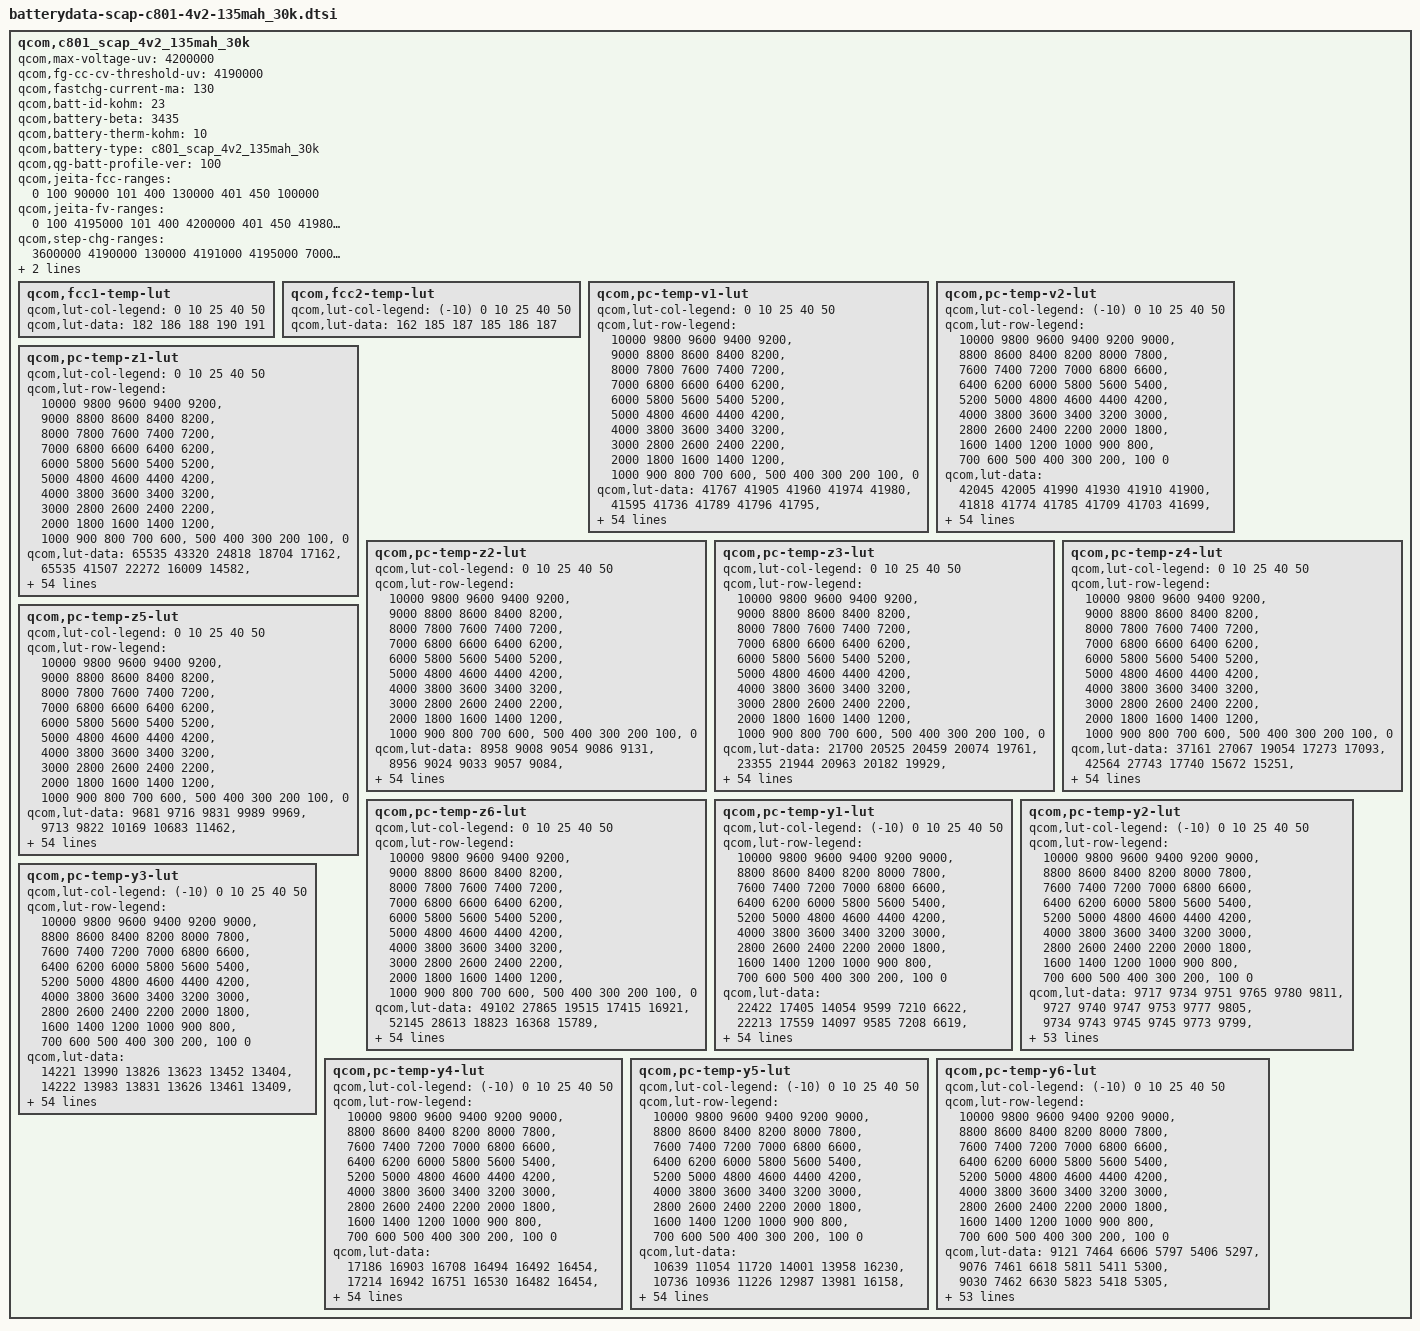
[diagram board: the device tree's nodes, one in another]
/* Copyright (c) 2015-2016, The Linux Foundation. All rights reserved.
 *
 * This program is free software; you can redistribute it and/or modify
 * it under the terms of the GNU General Public License version 2 and
 * only version 2 as published by the Free Software Foundation.
 *
 * This program is distributed in the hope that it will be useful,
 * but WITHOUT ANY WARRANTY; without even the implied warranty of
 * MERCHANTABILITY or FITNESS FOR A PARTICULAR PURPOSE.  See the
 * GNU General Public License for more details.
 */

qcom,c801_scap_4v2_135mah_30k {
	/* #batterydata-scap-c801-4v2-135mah_30k_FG_averaged_MasterSlave_Apr8th2020*/
	qcom,max-voltage-uv = <4200000>;
	qcom,fg-cc-cv-threshold-uv = <4190000>;
	qcom,fastchg-current-ma = <130>;
	qcom,batt-id-kohm = <23>;
	qcom,battery-beta = <3435>;
	qcom,battery-therm-kohm = <10>;
	qcom,battery-type = "c801_scap_4v2_135mah_30k";
	qcom,qg-batt-profile-ver = <100>;

	qcom,jeita-fcc-ranges = <0   100  90000
				101  400  130000
				401  450  100000>;
	qcom,jeita-fv-ranges = <0   100  4195000
				101 400  4200000
				401 450  4198000>;
	qcom,step-chg-ranges = <3600000  4190000  130000
				4191000  4195000  70000
				4196000  4200000  50000>;

	/* COOL = 0 DegC, WARM = 45 DegC */
	qcom,jeita-soft-thresholds = <0x3730 0x0FB0>;
	/* COLD = -10 DegC, HOT = 50 DegC */
	qcom,jeita-hard-thresholds = <0x448E 0x0D8F>;

	qcom,fcc1-temp-lut {
		qcom,lut-col-legend = <0 10 25 40 50>;
		qcom,lut-data = <182 186 188 190 191>;
	};

	qcom,fcc2-temp-lut {
		qcom,lut-col-legend = <(-10) 0 10 25 40 50>;
		qcom,lut-data = <162 185 187 185 186 187>;
	};

	qcom,pc-temp-v1-lut {
		qcom,lut-col-legend = <0 10 25 40 50>;
		qcom,lut-row-legend = <10000 9800 9600 9400 9200>,
			<9000 8800 8600 8400 8200>,
			<8000 7800 7600 7400 7200>,
			<7000 6800 6600 6400 6200>,
			<6000 5800 5600 5400 5200>,
			<5000 4800 4600 4400 4200>,
			<4000 3800 3600 3400 3200>,
			<3000 2800 2600 2400 2200>,
			<2000 1800 1600 1400 1200>,
			<1000 900 800 700 600>,
			<500 400 300 200 100>,
			<0>;
		qcom,lut-data = <41767 41905 41960 41974 41980>,
			<41595 41736 41789 41796 41795>,
			<41416 41555 41609 41610 41608>,
			<41245 41375 41429 41424 41421>,
			<41107 41204 41249 41241 41238>,
			<41024 41063 41073 41061 41057>,
			<40894 40972 40929 40888 40881>,
			<40518 40797 40837 40756 40717>,
			<40198 40429 40625 40612 40564>,
			<39987 40142 40303 40371 40379>,
			<39845 39965 40072 40159 40201>,
			<39743 39843 39933 40019 40053>,
			<39660 39749 39837 39902 39917>,
			<39581 39664 39742 39782 39782>,
			<39426 39567 39630 39654 39650>,
			<39133 39419 39508 39523 39518>,
			<39054 39297 39399 39395 39379>,
			<38951 39205 39281 39233 39227>,
			<38840 39101 39161 39070 39070>,
			<38727 39006 39032 38933 38919>,
			<38622 38917 38857 38798 38780>,
			<38530 38828 38698 38668 38655>,
			<38439 38741 38590 38563 38549>,
			<38351 38660 38502 38472 38456>,
			<38265 38582 38425 38390 38370>,
			<38182 38506 38352 38313 38291>,
			<38102 38430 38283 38240 38218>,
			<38027 38351 38219 38174 38153>,
			<37954 38282 38161 38114 38094>,
			<37890 38223 38107 38059 38038>,
			<37837 38172 38062 38010 37988>,
			<37783 38126 38024 37967 37942>,
			<37727 38082 37987 37929 37899>,
			<37670 38034 37953 37893 37856>,
			<37616 37987 37922 37851 37801>,
			<37571 37950 37885 37803 37741>,
			<37523 37915 37843 37747 37681>,
			<37460 37873 37776 37676 37614>,
			<37414 37819 37686 37589 37534>,
			<37407 37749 37599 37503 37445>,
			<37431 37659 37500 37403 37341>,
			<37466 37543 37380 37274 37214>,
			<37475 37427 37261 37147 37086>,
			<37442 37315 37152 37031 36967>,
			<37320 37212 37081 36976 36910>,
			<37210 37140 37037 36942 36877>,
			<37174 37110 37018 36927 36864>,
			<37154 37080 36990 36896 36831>,
			<37074 37000 36876 36773 36701>,
			<36850 36736 36585 36477 36402>,
			<36452 36360 36212 36105 36030>,
			<35986 35897 35753 35645 35572>,
			<35394 35321 35171 35064 34993>,
			<34600 34545 34390 34284 34217>,
			<33389 33377 33202 33106 33048>,
			<30000 30000 30000 30000 30000>;
	};

	qcom,pc-temp-v2-lut {
		qcom,lut-col-legend = <(-10) 0 10 25 40 50>;
		qcom,lut-row-legend = <10000 9800 9600 9400 9200 9000>,
			<8800 8600 8400 8200 8000 7800>,
			<7600 7400 7200 7000 6800 6600>,
			<6400 6200 6000 5800 5600 5400>,
			<5200 5000 4800 4600 4400 4200>,
			<4000 3800 3600 3400 3200 3000>,
			<2800 2600 2400 2200 2000 1800>,
			<1600 1400 1200 1000 900 800>,
			<700 600 500 400 300 200>,
			<100 0>;
		qcom,lut-data = <42045 42005 41990 41930 41910 41900>,
			<41818 41774 41785 41709 41703 41699>,
			<41615 41563 41589 41506 41508 41506>,
			<41440 41375 41400 41320 41324 41321>,
			<41277 41190 41213 41138 41144 41141>,
			<41100 41010 41031 40962 40968 40965>,
			<40942 40898 40906 40842 40816 40796>,
			<40837 40789 40778 40727 40669 40633>,
			<40724 40517 40556 40494 40495 40470>,
			<40514 40193 40277 40237 40309 40305>,
			<40234 39884 39945 40007 40109 40137>,
			<39906 39679 39733 39866 39961 39990>,
			<39616 39543 39589 39777 39848 39858>,
			<39430 39439 39483 39669 39721 39722>,
			<39291 39345 39383 39540 39586 39586>,
			<39182 39242 39266 39360 39446 39444>,
			<39092 39128 39142 39180 39281 39286>,
			<39011 38996 39011 39025 39080 39109>,
			<38931 38869 38887 38888 38914 38941>,
			<38841 38746 38769 38766 38776 38787>,
			<38745 38629 38657 38655 38658 38661>,
			<38647 38518 38551 38553 38554 38552>,
			<38550 38412 38449 38457 38459 38454>,
			<38455 38313 38354 38369 38371 38366>,
			<38363 38223 38265 38288 38289 38285>,
			<38276 38137 38181 38210 38213 38210>,
			<38190 38053 38099 38135 38143 38140>,
			<38105 37975 38021 38067 38076 38073>,
			<38024 37900 37949 38002 38012 38012>,
			<37947 37831 37882 37941 37951 37952>,
			<37868 37765 37814 37881 37894 37892>,
			<37791 37712 37768 37831 37829 37829>,
			<37714 37673 37716 37775 37763 37760>,
			<37640 37630 37659 37713 37688 37667>,
			<37570 37585 37602 37644 37615 37575>,
			<37490 37537 37557 37580 37536 37493>,
			<37423 37484 37501 37521 37461 37414>,
			<37339 37427 37444 37466 37390 37335>,
			<37268 37356 37385 37404 37329 37270>,
			<37201 37291 37316 37327 37256 37199>,
			<37124 37233 37229 37239 37155 37097>,
			<37040 37177 37138 37151 37061 37000>,
			<36945 37117 37077 37028 36940 36882>,
			<36827 37050 37031 36939 36847 36788>,
			<36673 36970 36986 36912 36830 36773>,
			<36460 36842 36920 36883 36809 36749>,
			<36329 36748 36867 36853 36779 36720>,
			<36168 36608 36760 36788 36684 36620>,
			<35977 36421 36581 36616 36427 36342>,
			<35746 36173 36323 36308 36063 35989>,
			<35459 35861 35970 35911 35645 35575>,
			<35081 35444 35515 35407 35150 35073>,
			<34539 34878 34908 34774 34519 34432>,
			<33776 34050 34081 33933 33654 33554>,
			<32656 32779 32857 32559 32262 32141>,
			<31049 30092 30438 30331 30552 30544>;
	};

	qcom,pc-temp-z1-lut {
		qcom,lut-col-legend = <0 10 25 40 50>;
		qcom,lut-row-legend = <10000 9800 9600 9400 9200>,
			<9000 8800 8600 8400 8200>,
			<8000 7800 7600 7400 7200>,
			<7000 6800 6600 6400 6200>,
			<6000 5800 5600 5400 5200>,
			<5000 4800 4600 4400 4200>,
			<4000 3800 3600 3400 3200>,
			<3000 2800 2600 2400 2200>,
			<2000 1800 1600 1400 1200>,
			<1000 900 800 700 600>,
			<500 400 300 200 100>,
			<0>;
		qcom,lut-data = <65535 43320 24818 18704 17162>,
			<65535 41507 22272 16009 14582>,
			<65535 41113 22126 15951 14529>,
			<65535 41531 22114 15964 14538>,
			<65535 41579 22209 15978 14553>,
			<65535 41989 22253 15982 14554>,
			<59786 41353 22290 15990 14564>,
			<51736 41056 22335 16037 14571>,
			<48514 39747 22277 16031 14578>,
			<46794 38711 22269 16015 14567>,
			<45720 38634 22219 16003 14605>,
			<45345 38560 22208 16003 14584>,
			<44036 38786 22234 16033 14583>,
			<43542 38602 22333 16038 14595>,
			<39424 38845 22391 16055 14598>,
			<35287 36282 22371 16069 14615>,
			<35502 34942 22237 16071 14622>,
			<35636 35303 22338 16089 14623>,
			<35763 35694 22433 16117 14631>,
			<36016 36067 22505 16133 14643>,
			<36275 36389 22561 16156 14655>,
			<36451 36906 22613 16181 14664>,
			<36579 37530 22666 16190 14678>,
			<36848 37796 22689 16199 14688>,
			<37049 38032 22722 16220 14692>,
			<37186 38490 22755 16234 14697>,
			<37325 39020 22800 16243 14709>,
			<37443 39535 22858 16256 14717>,
			<37542 39745 22933 16269 14723>,
			<37673 39829 22999 16282 14726>,
			<37896 39865 23058 16297 14731>,
			<38065 39975 23108 16317 14743>,
			<38217 40298 23110 16343 14758>,
			<38555 40574 23115 16373 14777>,
			<38990 40768 23219 16401 14803>,
			<39281 40971 23322 16432 14822>,
			<39600 41177 23413 16465 14828>,
			<40003 41343 23504 16486 14836>,
			<40544 41483 23607 16501 14848>,
			<41294 41665 23702 16526 14864>,
			<42191 41704 23739 16547 14880>,
			<43414 41617 23742 16558 14890>,
			<45722 41518 23755 16573 14898>,
			<48703 41345 23790 16595 14905>,
			<51740 41274 23862 16620 14918>,
			<53244 41626 23876 16634 14930>,
			<53816 41866 23865 16637 14933>,
			<53957 41193 23878 16636 14932>,
			<54066 41423 23937 16641 14937>,
			<54988 41400 24014 16685 14966>,
			<54106 41827 24190 16738 14997>,
			<54252 42128 24266 16812 15042>,
			<55592 42034 24522 16894 15085>,
			<54264 42643 24807 17026 15192>,
			<54264 42643 24807 17026 15192>,
			<54264 42643 24807 17026 15192>;
	};

	qcom,pc-temp-z2-lut {
		qcom,lut-col-legend = <0 10 25 40 50>;
		qcom,lut-row-legend = <10000 9800 9600 9400 9200>,
			<9000 8800 8600 8400 8200>,
			<8000 7800 7600 7400 7200>,
			<7000 6800 6600 6400 6200>,
			<6000 5800 5600 5400 5200>,
			<5000 4800 4600 4400 4200>,
			<4000 3800 3600 3400 3200>,
			<3000 2800 2600 2400 2200>,
			<2000 1800 1600 1400 1200>,
			<1000 900 800 700 600>,
			<500 400 300 200 100>,
			<0>;
		qcom,lut-data = <8958 9008 9054 9086 9131>,
			<8956 9024 9033 9057 9084>,
			<8979 9031 9034 9059 9098>,
			<8981 9032 9036 9067 9097>,
			<8962 9037 9042 9067 9100>,
			<8954 9037 9046 9067 9097>,
			<8959 9041 9046 9065 9098>,
			<8987 9039 9048 9067 9096>,
			<8971 9047 9045 9065 9099>,
			<8973 9060 9043 9062 9094>,
			<8975 9066 9047 9064 9096>,
			<8978 9066 9049 9067 9097>,
			<8978 9063 9049 9072 9098>,
			<8979 9055 9048 9070 9099>,
			<8983 9069 9050 9071 9099>,
			<8988 9047 9049 9069 9095>,
			<8989 9024 9035 9060 9092>,
			<8988 9024 9034 9058 9088>,
			<8987 9025 9034 9058 9087>,
			<8987 9024 9034 9058 9083>,
			<8986 9020 9032 9057 9080>,
			<8984 9019 9031 9056 9079>,
			<8983 9019 9032 9053 9078>,
			<8982 9019 9032 9051 9076>,
			<8981 9018 9032 9051 9075>,
			<8978 9017 9031 9051 9075>,
			<8977 9019 9030 9049 9077>,
			<8976 9041 9029 9049 9080>,
			<8975 9045 9028 9049 9085>,
			<8975 9042 9027 9052 9087>,
			<8975 9040 9026 9052 9089>,
			<8976 9038 9026 9052 9092>,
			<8976 9038 9024 9053 9091>,
			<8976 9043 9023 9054 9089>,
			<8976 9057 9024 9056 9096>,
			<8978 9056 9024 9057 9102>,
			<8979 9053 9023 9057 9098>,
			<8982 9050 9024 9056 9099>,
			<8982 9046 9025 9055 9103>,
			<8983 9039 9024 9057 9104>,
			<8987 9032 9023 9058 9103>,
			<8995 9023 9023 9056 9100>,
			<9000 9016 9021 9054 9099>,
			<9001 9011 9016 9052 9099>,
			<9002 9009 9013 9051 9098>,
			<9006 9008 9013 9051 9097>,
			<8998 9008 9015 9051 9098>,
			<8957 9014 9018 9055 9107>,
			<8954 9013 9020 9063 9108>,
			<8954 9006 9018 9062 9103>,
			<8969 9003 9013 9058 9095>,
			<8973 8995 9009 9053 9093>,
			<8973 8986 9005 9047 9082>,
			<8970 8981 9000 9040 9077>,
			<8970 8981 9000 9040 9077>,
			<8970 8981 9000 9040 9077>;
	};

	qcom,pc-temp-z3-lut {
		qcom,lut-col-legend = <0 10 25 40 50>;
		qcom,lut-row-legend = <10000 9800 9600 9400 9200>,
			<9000 8800 8600 8400 8200>,
			<8000 7800 7600 7400 7200>,
			<7000 6800 6600 6400 6200>,
			<6000 5800 5600 5400 5200>,
			<5000 4800 4600 4400 4200>,
			<4000 3800 3600 3400 3200>,
			<3000 2800 2600 2400 2200>,
			<2000 1800 1600 1400 1200>,
			<1000 900 800 700 600>,
			<500 400 300 200 100>,
			<0>;
		qcom,lut-data = <21700 20525 20459 20074 19761>,
			<23355 21944 20963 20182 19929>,
			<23936 22381 20978 20074 19829>,
			<24263 22491 20816 20006 19821>,
			<24259 22375 20620 19995 19806>,
			<25067 22254 20560 20007 19813>,
			<31310 22053 20527 20006 19813>,
			<28655 21908 20473 19969 19811>,
			<22527 21796 20537 20009 19807>,
			<21379 21497 20602 19996 19836>,
			<20995 21208 20498 19982 19817>,
			<20770 21127 20400 19928 19790>,
			<20664 21082 20411 19905 19783>,
			<20565 21002 20412 19886 19753>,
			<20367 21151 20362 19889 19777>,
			<20627 21236 20362 19920 19775>,
			<20705 21209 20746 20027 19815>,
			<20723 21202 20748 20191 19900>,
			<20715 21160 20866 20233 19943>,
			<20687 21106 21116 20226 20042>,
			<20652 21034 21203 20264 20087>,
			<20589 20979 21231 20356 20093>,
			<20495 20911 21202 20329 20060>,
			<20366 20809 21153 20268 20018>,
			<20222 20744 21088 20185 20013>,
			<20088 20713 21040 20170 20004>,
			<20000 20766 21000 20175 19965>,
			<19937 21704 20961 20175 19903>,
			<19888 21937 20949 20175 19842>,
			<19838 21929 20962 20153 19828>,
			<19786 21721 20944 20132 19815>,
			<19767 21476 20897 20119 19792>,
			<19763 21583 20925 20101 19802>,
			<19765 22082 20964 20080 19834>,
			<19759 23359 20990 20068 19820>,
			<19709 23391 21001 20056 19808>,
			<19663 23254 20995 20044 19811>,
			<19634 23264 21043 20051 19803>,
			<19634 23375 21109 20071 19785>,
			<19663 23531 21075 20044 19787>,
			<19594 23741 21066 20022 19793>,
			<19464 24030 21173 20056 19803>,
			<19424 23944 21172 20087 19819>,
			<19457 23593 21090 20108 19838>,
			<22510 23199 21029 20023 19787>,
			<24568 22345 20831 19928 19723>,
			<24046 21673 20624 19906 19707>,
			<20300 21027 20456 19856 19686>,
			<20136 20852 20484 19837 19717>,
			<20172 21418 20534 19866 19765>,
			<22384 21708 20558 19892 19782>,
			<22629 22012 20576 19926 19792>,
			<23184 22086 20639 19947 19822>,
			<23534 22193 20637 20003 19835>,
			<23534 22193 20637 20003 19835>,
			<23534 22193 20637 20003 19835>;
	};

	qcom,pc-temp-z4-lut {
		qcom,lut-col-legend = <0 10 25 40 50>;
		qcom,lut-row-legend = <10000 9800 9600 9400 9200>,
			<9000 8800 8600 8400 8200>,
			<8000 7800 7600 7400 7200>,
			<7000 6800 6600 6400 6200>,
			<6000 5800 5600 5400 5200>,
			<5000 4800 4600 4400 4200>,
			<4000 3800 3600 3400 3200>,
			<3000 2800 2600 2400 2200>,
			<2000 1800 1600 1400 1200>,
			<1000 900 800 700 600>,
			<500 400 300 200 100>,
			<0>;
		qcom,lut-data = <37161 27067 19054 17273 17093>,
			<42564 27743 17740 15672 15251>,
			<40139 23761 16538 15234 14985>,
			<36522 21453 16039 15146 14977>,
			<34327 20043 15740 15151 14981>,
			<32622 19270 15640 15123 14970>,
			<29851 18723 15678 15134 14965>,
			<24200 18032 15627 15172 14977>,
			<25022 17293 15512 15090 14949>,
			<24197 16794 15484 15087 14916>,
			<23452 16642 15582 15119 14933>,
			<23126 16703 15633 15150 14955>,
			<22861 16716 15574 15142 14949>,
			<22382 16732 15551 15152 14965>,
			<23514 16577 15585 15140 14938>,
			<26911 19062 15576 15120 14953>,
			<26807 21107 16025 15243 15061>,
			<26889 21007 15968 15555 15327>,
			<27081 20984 15837 15839 15497>,
			<27380 20962 15697 16026 15613>,
			<27669 20933 16273 16114 15683>,
			<27916 20939 16819 16165 15723>,
			<28224 20961 16915 16123 15685>,
			<28609 21022 16911 16046 15583>,
			<29044 21075 16824 15950 15476>,
			<29499 21114 16747 15827 15397>,
			<29923 21064 16670 15689 15351>,
			<30327 20053 16588 15581 15337>,
			<30745 19830 16495 15496 15326>,
			<31109 19880 16386 15438 15291>,
			<31400 20128 16291 15403 15268>,
			<31713 20382 16202 15380 15261>,
			<32049 20246 16068 15379 15262>,
			<32417 19659 15944 15385 15272>,
			<32799 18209 15856 15440 15363>,
			<33137 18146 15821 15499 15428>,
			<33478 18207 15816 15531 15382>,
			<33913 18095 15888 15578 15370>,
			<34166 17919 16023 15626 15378>,
			<33805 17727 16078 15574 15329>,
			<33192 17603 16130 15537 15278>,
			<32332 17527 16196 15702 15351>,
			<31385 17607 16232 15746 15404>,
			<30252 17802 16250 15723 15429>,
			<25686 17839 15943 15511 15298>,
			<20958 17969 15675 15163 15027>,
			<19856 18079 15606 15026 14913>,
			<20795 17316 15396 14978 14879>,
			<20507 16985 15319 15054 14878>,
			<20324 16471 15468 15102 14871>,
			<18420 16529 15540 15101 14877>,
			<18443 16499 15640 15110 14896>,
			<18426 16780 15713 15143 14915>,
			<18543 17026 15884 15157 14952>,
			<18543 17026 15884 15157 14952>,
			<18543 17026 15884 15157 14952>;
	};

	qcom,pc-temp-z5-lut {
		qcom,lut-col-legend = <0 10 25 40 50>;
		qcom,lut-row-legend = <10000 9800 9600 9400 9200>,
			<9000 8800 8600 8400 8200>,
			<8000 7800 7600 7400 7200>,
			<7000 6800 6600 6400 6200>,
			<6000 5800 5600 5400 5200>,
			<5000 4800 4600 4400 4200>,
			<4000 3800 3600 3400 3200>,
			<3000 2800 2600 2400 2200>,
			<2000 1800 1600 1400 1200>,
			<1000 900 800 700 600>,
			<500 400 300 200 100>,
			<0>;
		qcom,lut-data = <9681 9716 9831 9989 9969>,
			<9713 9822 10169 10683 11462>,
			<9751 9928 10373 10861 11885>,
			<9779 10039 10434 11000 11827>,
			<9776 10114 10499 10938 11559>,
			<9782 10147 10567 10967 11727>,
			<9810 10184 10454 10893 11664>,
			<9959 10225 10444 10742 11526>,
			<9761 10474 10534 10944 11570>,
			<9753 10610 10606 10823 11948>,
			<9753 10543 10399 10747 11706>,
			<9752 10462 10313 10611 11397>,
			<9757 10394 10372 10560 11230>,
			<9771 10326 10370 10488 11021>,
			<10147 10434 10281 10508 11270>,
			<10881 10365 10305 10646 11297>,
			<10886 10187 10140 10753 11273>,
			<10871 10160 10179 11650 11182>,
			<10836 10128 10441 11912 11004>,
			<10805 10086 11102 11101 11123>,
			<10772 10033 11775 10934 11149>,
			<10726 9994 12057 10939 10890>,
			<10674 9956 11644 10758 10667>,
			<10622 9914 11225 10499 10559>,
			<10568 9881 10896 10343 10645>,
			<10515 9859 10690 10333 10720>,
			<10467 9862 10553 10409 10749>,
			<10425 10076 10448 10512 10667>,
			<10393 10124 10414 10637 10559>,
			<10364 10111 10427 10743 10636>,
			<10331 10027 10408 10857 10732>,
			<10296 9930 10360 10982 10783>,
			<10264 9944 10411 11062 10994>,
			<10247 10026 10510 11105 11331>,
			<10233 10249 10629 11088 11182>,
			<10206 10239 10710 11040 11040>,
			<10176 10176 10776 10911 11022>,
			<10149 10171 11007 10938 10999>,
			<10113 10203 11280 11050 10962>,
			<10053 10251 11047 10952 11054>,
			<9981 10338 10938 10858 11143>,
			<9898 10497 11204 10853 10961>,
			<9806 10441 11140 10847 10865>,
			<9746 10248 10785 10836 10840>,
			<9966 10109 10672 10724 10857>,
			<10082 9921 10365 10791 11259>,
			<10022 9849 10137 11058 11874>,
			<9743 9865 10202 11233 11959>,
			<9730 9877 10743 10899 11934>,
			<9732 10160 10616 10722 12283>,
			<10039 10223 10507 10729 12423>,
			<10031 10318 10371 10761 12330>,
			<10080 10174 10305 10656 12494>,
			<10070 10094 10135 10673 12158>,
			<10070 10094 10135 10673 12158>,
			<10070 10094 10135 10673 12158>;
	};

	qcom,pc-temp-z6-lut {
		qcom,lut-col-legend = <0 10 25 40 50>;
		qcom,lut-row-legend = <10000 9800 9600 9400 9200>,
			<9000 8800 8600 8400 8200>,
			<8000 7800 7600 7400 7200>,
			<7000 6800 6600 6400 6200>,
			<6000 5800 5600 5400 5200>,
			<5000 4800 4600 4400 4200>,
			<4000 3800 3600 3400 3200>,
			<3000 2800 2600 2400 2200>,
			<2000 1800 1600 1400 1200>,
			<1000 900 800 700 600>,
			<500 400 300 200 100>,
			<0>;
		qcom,lut-data = <49102 27865 19515 17415 16921>,
			<52145 28613 18823 16368 15789>,
			<51812 27203 18292 16109 15603>,
			<50623 26317 17997 16028 15597>,
			<49758 25717 17767 16028 15593>,
			<49097 25382 17699 16025 15592>,
			<45015 25085 17704 16031 15592>,
			<36034 24684 17664 16035 15597>,
			<31011 24054 17640 16019 15586>,
			<29262 23476 17658 16011 15584>,
			<28257 23148 17637 16013 15584>,
			<27779 23109 17602 15999 15579>,
			<27308 23140 17591 15988 15572>,
			<26665 23119 17593 15983 15568>,
			<25765 23070 17593 15983 15568>,
			<25856 23293 17585 15991 15576>,
			<25909 23715 17980 16107 15647>,
			<26016 23743 17973 16336 15811>,
			<26152 23830 17992 16482 15912>,
			<26323 23892 18076 16556 16018>,
			<26483 23963 18388 16633 16075>,
			<26613 24055 18628 16700 16099>,
			<26758 24163 18665 16673 16070>,
			<26921 24269 18655 16612 16003>,
			<27097 24388 18587 16535 15957>,
			<27289 24526 18537 16471 15916>,
			<27496 24667 18495 16420 15878>,
			<27707 24841 18454 16376 15838>,
			<27925 24976 18418 16338 15802>,
			<28130 25074 18387 16304 15778>,
			<28310 25132 18347 16279 15760>,
			<28507 25181 18294 16261 15745>,
			<28724 25242 18253 16251 15748>,
			<28969 25329 18229 16248 15771>,
			<29226 25440 18220 16269 15810>,
			<29459 25494 18222 16294 15832>,
			<29710 25514 18237 16308 15817>,
			<30059 25500 18308 16336 15809>,
			<30306 25497 18416 16370 15803>,
			<30389 25522 18437 16340 15786>,
			<30364 25567 18470 16319 15772>,
			<30413 25669 18569 16412 15812>,
			<30779 25653 18583 16452 15849>,
			<31493 25557 18562 16460 15874>,
			<32868 25389 18427 16336 15793>,
			<33799 25055 18205 16142 15644>,
			<33867 24749 18080 16072 15587>,
			<32974 24103 17884 16010 15550>,
			<32833 23874 17866 16027 15564>,
			<32817 23962 17984 16078 15593>,
			<33120 24182 18068 16108 15614>,
			<33213 24386 18168 16151 15641>,
			<33463 24600 18292 16202 15677>,
			<33681 24887 18466 16278 15729>,
			<33681 24887 18466 16278 15729>,
			<33681 24887 18466 16278 15729>;
	};

	qcom,pc-temp-y1-lut {
		qcom,lut-col-legend = <(-10) 0 10 25 40 50>;
		qcom,lut-row-legend = <10000 9800 9600 9400 9200 9000>,
			<8800 8600 8400 8200 8000 7800>,
			<7600 7400 7200 7000 6800 6600>,
			<6400 6200 6000 5800 5600 5400>,
			<5200 5000 4800 4600 4400 4200>,
			<4000 3800 3600 3400 3200 3000>,
			<2800 2600 2400 2200 2000 1800>,
			<1600 1400 1200 1000 900 800>,
			<700 600 500 400 300 200>,
			<100 0>;
		qcom,lut-data = <22422 17405 14054 9599 7210 6622>,
			<22213 17559 14097 9585 7208 6619>,
			<21916 17611 14105 9563 7208 6618>,
			<21646 17602 14089 9545 7208 6618>,
			<21520 17543 14049 9542 7212 6620>,
			<21537 17421 13976 9544 7220 6625>,
			<21584 17446 13959 9529 7222 6629>,
			<21676 17517 13957 9506 7222 6632>,
			<21779 17561 13960 9517 7220 6632>,
			<21789 17606 13989 9554 7225 6634>,
			<21812 17680 14152 9700 7297 6652>,
			<22047 17754 14264 9785 7334 6663>,
			<22140 17845 14335 9823 7350 6669>,
			<22057 17887 14346 9816 7343 6668>,
			<22107 17882 14338 9791 7335 6668>,
			<22068 17887 14272 9752 7340 6672>,
			<21950 17866 14220 9736 7347 6677>,
			<22418 17751 14190 9740 7356 6681>,
			<23478 17735 14200 9749 7363 6688>,
			<23218 17786 14217 9768 7370 6696>,
			<22187 17829 14199 9771 7378 6698>,
			<21979 17841 14190 9773 7385 6699>,
			<22084 17832 14242 9792 7391 6702>,
			<22113 17845 14278 9809 7395 6706>,
			<22125 17882 14298 9816 7400 6711>,
			<22165 17875 14278 9829 7407 6716>,
			<22174 17833 14255 9846 7415 6721>,
			<22261 17869 14298 9856 7420 6726>,
			<22359 17882 14334 9871 7428 6733>,
			<22305 17906 14363 9924 7445 6742>,
			<22159 18113 14564 9993 7464 6750>,
			<22050 18210 14822 10092 7501 6762>,
			<22024 19166 14924 10231 7522 6770>,
			<22111 18242 14994 10244 7537 6777>,
			<22451 18215 14959 10248 7550 6783>,
			<22211 18447 15000 10302 7559 6790>,
			<22348 18520 14985 10317 7564 6795>,
			<22384 18296 15048 10329 7568 6799>,
			<22235 18346 14991 10326 7576 6803>,
			<22440 18327 15129 10350 7582 6808>,
			<22442 18379 15070 10343 7592 6815>,
			<22330 18357 15064 10379 7603 6820>,
			<22400 18554 15070 10401 7611 6825>,
			<22478 18484 15116 10384 7624 6837>,
			<22689 18528 15121 10421 7632 6841>,
			<22663 18594 15137 10426 7638 6845>,
			<23007 18664 15219 10443 7638 6847>,
			<23465 18624 15211 10451 7644 6852>,
			<24002 18724 15367 10474 7657 6859>,
			<24805 18691 15191 10542 7696 6884>,
			<25626 18915 15352 10569 7738 6912>,
			<27224 19040 15457 10666 7795 6946>,
			<29299 19031 15626 10784 7863 6997>,
			<32438 20147 15784 10941 7964 7063>,
			<32438 20147 15784 10941 7964 7063>,
			<32438 20147 15784 10941 7964 7063>;
	};

	qcom,pc-temp-y2-lut {
		qcom,lut-col-legend = <(-10) 0 10 25 40 50>;
		qcom,lut-row-legend = <10000 9800 9600 9400 9200 9000>,
			<8800 8600 8400 8200 8000 7800>,
			<7600 7400 7200 7000 6800 6600>,
			<6400 6200 6000 5800 5600 5400>,
			<5200 5000 4800 4600 4400 4200>,
			<4000 3800 3600 3400 3200 3000>,
			<2800 2600 2400 2200 2000 1800>,
			<1600 1400 1200 1000 900 800>,
			<700 600 500 400 300 200>,
			<100 0>;
		qcom,lut-data = <9717 9734 9751 9765 9780 9811>,
			<9727 9740 9747 9753 9777 9805>,
			<9734 9743 9745 9745 9773 9799>,
			<9737 9744 9744 9741 9770 9794>,
			<9738 9743 9744 9741 9767 9790>,
			<9736 9738 9744 9746 9765 9786>,
			<9732 9735 9742 9744 9763 9784>,
			<9731 9734 9739 9741 9762 9784>,
			<9731 9739 9740 9741 9762 9784>,
			<9736 9746 9744 9743 9764 9785>,
			<9742 9750 9753 9753 9769 9791>,
			<9744 9750 9753 9759 9770 9794>,
			<9745 9748 9749 9761 9769 9797>,
			<9742 9747 9749 9764 9770 9801>,
			<9741 9746 9749 9765 9772 9805>,
			<9741 9747 9749 9758 9775 9806>,
			<9741 9748 9749 9751 9776 9807>,
			<9742 9747 9749 9750 9775 9809>,
			<9742 9747 9749 9750 9776 9808>,
			<9742 9747 9749 9749 9777 9806>,
			<9741 9746 9749 9749 9777 9809>,
			<9741 9745 9748 9749 9777 9811>,
			<9741 9744 9747 9748 9777 9812>,
			<9741 9743 9747 9748 9777 9812>,
			<9741 9743 9746 9748 9779 9814>,
			<9741 9744 9746 9748 9780 9815>,
			<9740 9743 9746 9745 9781 9817>,
			<9739 9743 9743 9745 9782 9820>,
			<9739 9743 9743 9745 9782 9823>,
			<9741 9748 9746 9745 9783 9827>,
			<9741 9756 9755 9748 9786 9834>,
			<9741 9797 9800 9759 9805 9863>,
			<9743 9842 9808 9792 9818 9874>,
			<9748 9837 9814 9790 9817 9865>,
			<9760 9836 9803 9785 9810 9863>,
			<9740 9827 9816 9780 9808 9861>,
			<9745 9835 9796 9780 9806 9857>,
			<9710 9835 9806 9778 9806 9854>,
			<9716 9822 9799 9773 9806 9857>,
			<9721 9828 9798 9773 9805 9860>,
			<9716 9826 9788 9766 9804 9858>,
			<9719 9825 9786 9765 9804 9860>,
			<9721 9819 9788 9764 9803 9865>,
			<9731 9827 9786 9757 9792 9850>,
			<9779 9834 9789 9759 9787 9836>,
			<9775 9840 9802 9761 9789 9831>,
			<9766 9845 9812 9762 9790 9832>,
			<9761 9840 9810 9764 9797 9834>,
			<9749 9834 9805 9764 9800 9851>,
			<9737 9826 9797 9759 9799 9838>,
			<9731 9819 9786 9751 9793 9845>,
			<9718 9804 9770 9748 9785 9826>,
			<9701 9791 9754 9740 9775 9814>,
			<9684 9765 9755 9731 9761 9801>,
			<9684 9765 9755 9731 9761 9801>,
			<9684 9765 9755 9731 9761 9801>;
	};

	qcom,pc-temp-y3-lut {
		qcom,lut-col-legend = <(-10) 0 10 25 40 50>;
		qcom,lut-row-legend = <10000 9800 9600 9400 9200 9000>,
			<8800 8600 8400 8200 8000 7800>,
			<7600 7400 7200 7000 6800 6600>,
			<6400 6200 6000 5800 5600 5400>,
			<5200 5000 4800 4600 4400 4200>,
			<4000 3800 3600 3400 3200 3000>,
			<2800 2600 2400 2200 2000 1800>,
			<1600 1400 1200 1000 900 800>,
			<700 600 500 400 300 200>,
			<100 0>;
		qcom,lut-data = <14221 13990 13826 13623 13452 13404>,
			<14222 13983 13831 13626 13461 13409>,
			<14228 13985 13836 13630 13469 13414>,
			<14234 13990 13841 13634 13477 13421>,
			<14237 13993 13846 13639 13483 13428>,
			<14236 13999 13851 13644 13488 13435>,
			<14241 14037 13876 13663 13499 13443>,
			<14283 14084 13906 13686 13511 13450>,
			<14319 14067 13911 13671 13514 13455>,
			<14313 14036 13902 13655 13515 13461>,
			<14292 13988 13853 13648 13510 13468>,
			<14229 13972 13834 13650 13508 13468>,
			<14180 13967 13827 13666 13507 13462>,
			<14168 13974 13839 13669 13498 13455>,
			<14164 13985 13849 13670 13489 13445>,
			<14172 13983 13841 13644 13493 13436>,
			<14187 13980 13834 13619 13493 13430>,
			<14195 13972 13829 13607 13474 13426>,
			<14197 13969 13826 13607 13467 13417>,
			<14196 13969 13824 13612 13464 13407>,
			<14195 13964 13823 13612 13468 13407>,
			<14195 13962 13821 13611 13472 13407>,
			<14196 13959 13816 13607 13472 13410>,
			<14197 13957 13813 13606 13472 13418>,
			<14198 13965 13814 13613 13472 13429>,
			<14200 13969 13815 13611 13471 13428>,
			<14202 13969 13814 13602 13471 13425>,
			<14203 13969 13812 13602 13471 13424>,
			<14207 13966 13807 13602 13468 13424>,
			<14214 13933 13787 13592 13457 13416>,
			<14221 13875 13734 13575 13445 13397>,
			<14228 13689 13561 13536 13397 13354>,
			<14218 13536 13513 13450 13374 13342>,
			<14185 13545 13518 13454 13373 13343>,
			<14105 13544 13516 13442 13376 13340>,
			<13908 13545 13486 13449 13373 13343>,
			<13828 13549 13524 13454 13373 13342>,
			<13660 13555 13528 13456 13374 13342>,
			<13672 13558 13533 13460 13375 13343>,
			<13680 13558 13535 13459 13374 13343>,
			<13683 13566 13533 13469 13375 13343>,
			<13690 13573 13545 13461 13377 13347>,
			<13702 13578 13554 13463 13371 13342>,
			<13715 13590 13559 13477 13379 13341>,
			<13725 13610 13541 13492 13391 13355>,
			<13749 13637 13574 13495 13410 13369>,
			<13788 13635 13579 13493 13409 13374>,
			<13803 13644 13584 13486 13398 13377>,
			<13895 13654 13586 13481 13386 13352>,
			<13937 13667 13598 13473 13390 13366>,
			<14042 13683 13600 13489 13404 13361>,
			<14202 13715 13612 13484 13418 13372>,
			<14445 13740 13636 13527 13429 13379>,
			<15130 13863 13694 13576 13452 13396>,
			<15130 13863 13694 13576 13452 13396>,
			<15130 13863 13694 13576 13452 13396>;
	};

	qcom,pc-temp-y4-lut {
		qcom,lut-col-legend = <(-10) 0 10 25 40 50>;
		qcom,lut-row-legend = <10000 9800 9600 9400 9200 9000>,
			<8800 8600 8400 8200 8000 7800>,
			<7600 7400 7200 7000 6800 6600>,
			<6400 6200 6000 5800 5600 5400>,
			<5200 5000 4800 4600 4400 4200>,
			<4000 3800 3600 3400 3200 3000>,
			<2800 2600 2400 2200 2000 1800>,
			<1600 1400 1200 1000 900 800>,
			<700 600 500 400 300 200>,
			<100 0>;
		qcom,lut-data = <17186 16903 16708 16494 16492 16454>,
			<17214 16942 16751 16530 16482 16454>,
			<17247 16983 16799 16567 16481 16456>,
			<17278 17018 16837 16597 16488 16458>,
			<17300 17040 16853 16612 16499 16461>,
			<17312 17056 16862 16620 16516 16467>,
			<17323 17085 16886 16645 16529 16477>,
			<17338 17109 16910 16683 16542 16490>,
			<17353 17102 16917 16709 16561 16507>,
			<17359 17098 16919 16732 16588 16526>,
			<17357 17110 16917 16753 16628 16543>,
			<17338 17115 16920 16776 16674 16577>,
			<17318 17115 16925 16800 16722 16629>,
			<17308 17111 16910 16794 16763 16678>,
			<17297 17105 16896 16772 16782 16712>,
			<17280 17107 16897 16736 16763 16727>,
			<17273 17103 16894 16701 16719 16716>,
			<17281 17086 16878 16678 16635 16640>,
			<17296 17072 16872 16654 16585 16588>,
			<17308 17060 16870 16633 16555 16551>,
			<17320 17056 16871 16635 16536 16531>,
			<17324 17054 16875 16642 16529 16523>,
			<17330 17059 16886 16662 16540 16522>,
			<17341 17063 16893 16674 16554 16521>,
			<17363 17055 16896 16678 16573 16518>,
			<17381 17054 16900 16693 16595 16535>,
			<17403 17064 16908 16728 16617 16571>,
			<17430 17070 16917 16747 16638 16598>,
			<17444 17071 16918 16759 16659 16616>,
			<17457 17056 16904 16764 16672 16635>,
			<17477 17031 16870 16741 16666 16637>,
			<17496 16922 16746 16674 16586 16551>,
			<17499 16819 16705 16581 16533 16513>,
			<17481 16820 16696 16570 16523 16511>,
			<17424 16815 16703 16574 16514 16494>,
			<17268 16815 16681 16570 16510 16481>,
			<17186 16801 16698 16558 16498 16474>,
			<17038 16791 16679 16553 16486 16467>,
			<17052 16807 16677 16555 16488 16466>,
			<17053 16806 16671 16544 16495 16470>,
			<17053 16806 16669 16536 16483 16462>,
			<17074 16817 16651 16549 16489 16463>,
			<17089 16850 16649 16527 16491 16465>,
			<17105 16870 16689 16515 16465 16452>,
			<17123 16907 16735 16533 16488 16467>,
			<17159 16947 16795 16613 16525 16496>,
			<17217 16946 16812 16671 16567 16518>,
			<17250 16949 16818 16697 16573 16514>,
			<17390 16952 16804 16649 16522 16481>,
			<17470 16957 16791 16616 16520 16510>,
			<17668 16970 16775 16617 16561 16551>,
			<17968 17001 16785 16623 16632 16618>,
			<18447 17028 16817 16665 16713 16683>,
			<19970 17210 16893 16754 16856 16821>,
			<19970 17210 16893 16754 16856 16821>,
			<19970 17210 16893 16754 16856 16821>;
	};

	qcom,pc-temp-y5-lut {
		qcom,lut-col-legend = <(-10) 0 10 25 40 50>;
		qcom,lut-row-legend = <10000 9800 9600 9400 9200 9000>,
			<8800 8600 8400 8200 8000 7800>,
			<7600 7400 7200 7000 6800 6600>,
			<6400 6200 6000 5800 5600 5400>,
			<5200 5000 4800 4600 4400 4200>,
			<4000 3800 3600 3400 3200 3000>,
			<2800 2600 2400 2200 2000 1800>,
			<1600 1400 1200 1000 900 800>,
			<700 600 500 400 300 200>,
			<100 0>;
		qcom,lut-data = <10639 11054 11720 14001 13958 16230>,
			<10736 10936 11226 12987 13981 16158>,
			<10841 10829 10865 12103 13791 15990>,
			<10925 10771 10671 11557 13449 15753>,
			<10958 10800 10695 11560 12925 15418>,
			<10955 10880 10866 11889 12276 14814>,
			<10977 10924 10930 11869 12435 14114>,
			<11024 10952 10985 11743 12703 13352>,
			<11057 11037 11146 11485 12248 12515>,
			<11051 11087 11215 11385 11837 12269>,
			<11051 11046 11222 12025 11670 12427>,
			<11081 11058 11206 12821 11494 12171>,
			<11074 11129 11179 13712 11336 11538>,
			<11008 11150 11257 14481 11332 11372>,
			<10968 11165 11313 14921 11400 11291>,
			<11004 11088 11099 13327 12855 11621>,
			<11025 11067 11042 11891 13448 12279>,
			<11006 11054 11120 11457 12887 13501>,
			<10968 11068 11152 11483 12611 13269>,
			<10937 11114 11164 11766 12410 12510>,
			<10910 11066 11158 11757 12798 12256>,
			<10910 11027 11139 11667 13066 12157>,
			<10947 10952 11082 11438 12767 12169>,
			<10929 10889 11070 11377 12381 12504>,
			<10900 10996 11170 11700 11971 13417>,
			<10921 11026 11240 11658 11740 12936>,
			<10923 10992 11266 11323 11689 12033>,
			<10895 10973 11297 11383 11651 11802>,
			<10934 10969 11409 11507 11506 11850>,
			<11034 11026 11559 11622 11581 11754>,
			<11096 11059 11501 11872 11948 11734>,
			<11160 11337 11888 12935 12532 12972>,
			<11276 11537 11774 13012 13344 13958>,
			<11460 11597 11885 13335 13308 13101>,
			<11779 11589 11566 12022 13630 13149>,
			<11815 11496 11812 12055 12526 13805>,
			<12084 11597 11605 12296 12988 14271>,
			<11813 11655 11793 12413 13567 14837>,
			<11866 11186 11816 12379 13443 14932>,
			<12198 11197 11885 12647 13105 14561>,
			<12252 11367 11482 12854 13729 15339>,
			<12475 11462 11559 12510 13405 15165>,
			<12815 11429 11585 12899 13321 15013>,
			<13206 11932 11283 12403 15031 16414>,
			<13794 12925 11521 12956 13471 14852>,
			<13968 14146 12667 12068 13197 13061>,
			<13887 14751 14067 11829 12173 12645>,
			<13583 14850 14863 12444 12193 13043>,
			<13150 14796 15048 13309 13169 14021>,
			<12739 14558 14801 12245 13633 17018>,
			<12229 14403 13897 12470 15914 18714>,
			<11566 13983 13194 12249 17797 18352>,
			<10739 13502 12739 13412 17684 17772>,
			<10076 12563 13823 15540 16867 16939>,
			<10076 12563 13823 15540 16867 16939>,
			<10076 12563 13823 15540 16867 16939>;
	};

	qcom,pc-temp-y6-lut {
		qcom,lut-col-legend = <(-10) 0 10 25 40 50>;
		qcom,lut-row-legend = <10000 9800 9600 9400 9200 9000>,
			<8800 8600 8400 8200 8000 7800>,
			<7600 7400 7200 7000 6800 6600>,
			<6400 6200 6000 5800 5600 5400>,
			<5200 5000 4800 4600 4400 4200>,
			<4000 3800 3600 3400 3200 3000>,
			<2800 2600 2400 2200 2000 1800>,
			<1600 1400 1200 1000 900 800>,
			<700 600 500 400 300 200>,
			<100 0>;
		qcom,lut-data = <9121 7464 6606 5797 5406 5297>,
			<9076 7461 6618 5811 5411 5300>,
			<9030 7462 6630 5823 5418 5305>,
			<8989 7465 6640 5834 5426 5311>,
			<8958 7467 6645 5842 5435 5318>,
			<8935 7471 6648 5848 5445 5326>,
			<8923 7493 6668 5870 5458 5335>,
			<8933 7519 6690 5895 5470 5344>,
			<8940 7506 6693 5890 5478 5353>,
			<8932 7496 6692 5887 5487 5363>,
			<8916 7500 6687 5902 5500 5373>,
			<8912 7506 6689 5923 5516 5384>,
			<8914 7516 6694 5945 5531 5395>,
			<8924 7527 6699 5944 5532 5403>,
			<8937 7534 6700 5934 5532 5406>,
			<8955 7528 6687 5901 5528 5404>,
			<8975 7516 6671 5871 5517 5396>,
			<8988 7494 6657 5857 5480 5371>,
			<8991 7488 6655 5852 5460 5349>,
			<8984 7487 6654 5850 5451 5332>,
			<8981 7487 6655 5850 5450 5326>,
			<8979 7490 6655 5853 5450 5325>,
			<8980 7493 6657 5856 5454 5327>,
			<8989 7498 6659 5861 5459 5331>,
			<9009 7507 6662 5867 5464 5338>,
			<9029 7518 6666 5873 5470 5345>,
			<9047 7530 6669 5879 5477 5353>,
			<9066 7540 6673 5885 5484 5361>,
			<9088 7544 6675 5889 5487 5365>,
			<9113 7530 6672 5888 5485 5365>,
			<9145 7510 6646 5877 5476 5352>,
			<9172 7396 6524 5837 5419 5294>,
			<9175 7281 6490 5755 5387 5275>,
			<9156 7300 6498 5758 5386 5276>,
			<9085 7310 6504 5752 5387 5270>,
			<8909 7318 6485 5762 5386 5270>,
			<8835 7325 6517 5766 5383 5268>,
			<8689 7334 6518 5768 5383 5267>,
			<8723 7348 6524 5772 5385 5267>,
			<8747 7364 6532 5771 5387 5269>,
			<8763 7386 6532 5779 5386 5268>,
			<8808 7403 6539 5779 5390 5273>,
			<8841 7423 6548 5779 5388 5269>,
			<8888 7457 6568 5789 5391 5269>,
			<8944 7501 6575 5807 5408 5285>,
			<9025 7566 6626 5833 5432 5303>,
			<9152 7577 6642 5849 5442 5312>,
			<9294 7603 6653 5852 5436 5313>,
			<9585 7638 6663 5839 5413 5284>,
			<9832 7678 6682 5834 5423 5307>,
			<10253 7739 6701 5861 5453 5319>,
			<10877 7827 6741 5875 5493 5354>,
			<11832 7923 6810 5943 5538 5386>,
			<14168 8313 6941 6043 5617 5450>,
			<14168 8313 6941 6043 5617 5450>,
			<14168 8313 6941 6043 5617 5450>;
	};
};
